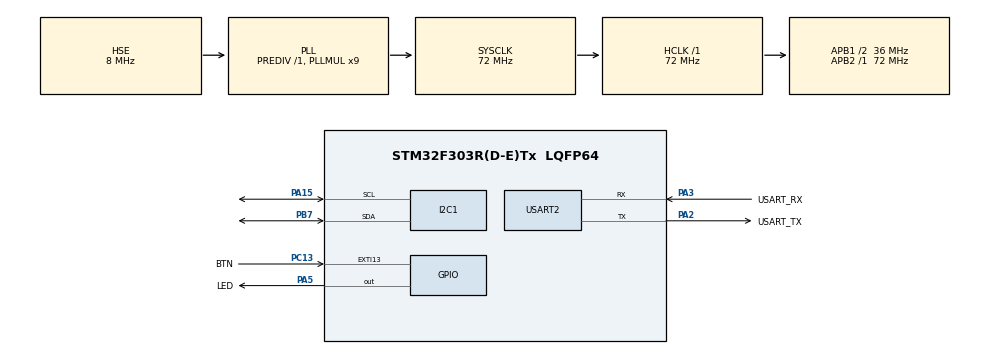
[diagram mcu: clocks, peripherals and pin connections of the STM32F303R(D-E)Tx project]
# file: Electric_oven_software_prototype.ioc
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Dma.I2C1_TX.0.Direction=DMA_MEMORY_TO_PERIPH
Dma.I2C1_TX.0.Instance=DMA1_Channel6
Dma.I2C1_TX.0.MemDataAlignment=DMA_MDATAALIGN_BYTE
Dma.I2C1_TX.0.MemInc=DMA_MINC_ENABLE
Dma.I2C1_TX.0.Mode=DMA_NORMAL
Dma.I2C1_TX.0.PeriphDataAlignment=DMA_PDATAALIGN_BYTE
Dma.I2C1_TX.0.PeriphInc=DMA_PINC_DISABLE
Dma.I2C1_TX.0.Priority=DMA_PRIORITY_LOW
Dma.Request0=I2C1_TX
I2C1.Timing=0x10C18DCC
Mcu.Family=STM32F3
Mcu.Name=STM32F303R(D-E)Tx
Mcu.Package=LQFP64
NVIC.DMA1_Channel6_IRQn=true\:0\:0\:false\:false\:true\:false\:true\:true
NVIC.I2C1_EV_IRQn=true\:0\:0\:false\:false\:true\:true\:true\:true
NVIC.PriorityGroup=NVIC_PRIORITYGROUP_0
PA13.GPIO_Label=TMS
PA13.Mode=Serial_Wire
PA13.Signal=SYS_JTMS-SWDIO
PA14.GPIO_Label=TCK
PA14.Mode=Serial_Wire
PA14.Signal=SYS_JTCK-SWCLK
PA15.Mode=I2C
PA15.Signal=I2C1_SCL
PA2.GPIO_Label=USART_TX
PA2.GPIO_Mode=GPIO_MODE_AF_PP
PA2.GPIO_PuPd=GPIO_NOPULL
PA2.GPIO_Speed=GPIO_SPEED_FREQ_LOW
PA2.Mode=Asynchronous
PA2.Signal=USART2_TX
PA3.GPIO_Label=USART_RX
PA3.GPIO_Mode=GPIO_MODE_AF_PP
PA3.GPIO_PuPd=GPIO_NOPULL
PA3.GPIO_Speed=GPIO_SPEED_FREQ_LOW
PA3.Mode=Asynchronous
PA3.Signal=USART2_RX
PA5.GPIO_Label=LED
PA5.GPIO_Mode=GPIO_MODE_OUTPUT_PP
PA5.GPIO_PuPd=GPIO_NOPULL
PA5.GPIO_Speed=GPIO_SPEED_FREQ_LOW
PA5.Signal=GPIO_Output
PB7.Mode=I2C
PB7.Signal=I2C1_SDA
PC13.GPIO_Label=BTN
PC13.GPIO_ModeDefaultEXTI=GPIO_MODE_IT_FALLING
PC13.Signal=GPXTI13
PF0-OSC_IN.Mode=HSE-External-Clock-Source
PF0-OSC_IN.Signal=RCC_OSC_IN
ProjectManager.HeapSize=0x200
ProjectManager.StackSize=0x400
ProjectManager.TargetToolchain=CMake
RCC.AHBFreq_Value=72000000
RCC.APB1CLKDivider=RCC_HCLK_DIV2
RCC.APB1Freq_Value=36000000
RCC.APB1TimFreq_Value=72000000
RCC.APB2Freq_Value=72000000
RCC.APB2TimFreq_Value=72000000
RCC.CortexFreq_Value=72000000
RCC.EnbaleCSS=true
RCC.HCLKFreq_Value=72000000
RCC.HSE_VALUE=8000000
RCC.HSI_VALUE=8000000
RCC.I2c1ClockSelection=RCC_I2C1CLKSOURCE_SYSCLK
RCC.LSE_VALUE=32768
RCC.PLLM=8
RCC.PLLMUL=RCC_PLL_MUL9
RCC.PLLN=336
RCC.PLLP=RCC_PLLP_DIV4
RCC.PLLQ=7
RCC.PLLSourceVirtual=RCC_PLLSOURCE_HSE
RCC.RCC_PLLsource_Clock_Source_FROM_HSE=RCC_HSE_PREDIV_DIV2
RCC.SYSCLKFreq_VALUE=72000000
RCC.SYSCLKSourceVirtual=RCC_SYSCLKSOURCE_PLLCLK
RCC.USBFreq_Value=72000000
USART2.VirtualMode-Asynchronous=VM_ASYNC
board=NUCLEO-F303RE

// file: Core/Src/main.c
/* USER CODE BEGIN Header */
/**
  ******************************************************************************
  * @file           : main.c
  * @brief          : Main program body
  ******************************************************************************
  * @attention
  *
  * Copyright (c) 2025 STMicroelectronics.
  * All rights reserved.
  *
  * This software is licensed under terms that can be found in the LICENSE file
  * in the root directory of this software component.
  * If no LICENSE file comes with this software, it is provided AS-IS.
  *
  ******************************************************************************
  */
  /* USER CODE END Header */
  /* Includes ------------------------------------------------------------------*/
#include "main.h"
#include "dma.h"
#include "i2c.h"
#include "usart.h"
#include "gpio.h"

/* USER CODE BEGIN Includes */
#include "LCD_HD44780_PCF8574_driver.h"
/* USER CODE END Includes */

void SystemClock_Config(void);

int main(void) {

    /* MCU Configuration--------------------------------------------------------*/

    /* Reset of all peripherals, Initializes the Flash interface and the Systick. */
    HAL_Init();

    /* Configure the system clock */
    SystemClock_Config();

    /* Initialize all configured peripherals */
    MX_GPIO_Init();
    MX_DMA_Init();
    MX_USART2_UART_Init();
    MX_I2C1_Init();
    /* USER CODE BEGIN 2 */

    lcdInit(&hi2c1, 0x27, 2, 8, true);

    /* USER CODE END 2 */

    /* Infinite loop */
    /* USER CODE BEGIN WHILE */
    while (1) {
        HAL_GPIO_TogglePin(LED_GPIO_Port, LED_Pin);
        HAL_Delay(250);
        /* USER CODE END WHILE */

    }
}

void SystemClock_Config(void) {
    RCC_OscInitTypeDef RCC_OscInitStruct = { 0 };
    RCC_ClkInitTypeDef RCC_ClkInitStruct = { 0 };
    RCC_PeriphCLKInitTypeDef PeriphClkInit = { 0 };

    /** Initializes the RCC Oscillators according to the specified parameters
    * in the RCC_OscInitTypeDef structure.
    */
    RCC_OscInitStruct.OscillatorType = RCC_OSCILLATORTYPE_HSE;
    RCC_OscInitStruct.HSEState = RCC_HSE_BYPASS;
    RCC_OscInitStruct.HSIState = RCC_HSI_ON;
    RCC_OscInitStruct.PLL.PLLState = RCC_PLL_ON;
    RCC_OscInitStruct.PLL.PLLSource = RCC_PLLSOURCE_HSE;
    RCC_OscInitStruct.PLL.PLLMUL = RCC_PLL_MUL9;
    RCC_OscInitStruct.PLL.PREDIV = RCC_PREDIV_DIV1;
    if (HAL_RCC_OscConfig(&RCC_OscInitStruct) != HAL_OK) {
        Error_Handler();
    }

    /** Initializes the CPU, AHB and APB buses clocks
    */
    RCC_ClkInitStruct.ClockType = RCC_CLOCKTYPE_HCLK | RCC_CLOCKTYPE_SYSCLK
        | RCC_CLOCKTYPE_PCLK1 | RCC_CLOCKTYPE_PCLK2;
    RCC_ClkInitStruct.SYSCLKSource = RCC_SYSCLKSOURCE_PLLCLK;
    RCC_ClkInitStruct.AHBCLKDivider = RCC_SYSCLK_DIV1;
    RCC_ClkInitStruct.APB1CLKDivider = RCC_HCLK_DIV2;
    RCC_ClkInitStruct.APB2CLKDivider = RCC_HCLK_DIV1;

    if (HAL_RCC_ClockConfig(&RCC_ClkInitStruct, FLASH_LATENCY_2) != HAL_OK) {
        Error_Handler();
    }
    PeriphClkInit.PeriphClockSelection = RCC_PERIPHCLK_USART2 | RCC_PERIPHCLK_I2C1;
    PeriphClkInit.Usart2ClockSelection = RCC_USART2CLKSOURCE_PCLK1;
    PeriphClkInit.I2c1ClockSelection = RCC_I2C1CLKSOURCE_SYSCLK;
    if (HAL_RCCEx_PeriphCLKConfig(&PeriphClkInit) != HAL_OK) {
        Error_Handler();
    }

    /** Enables the Clock Security System
    */
    HAL_RCC_EnableCSS();
}

void Error_Handler(void) {
    __disable_irq();
    while (1) {
    }
}
